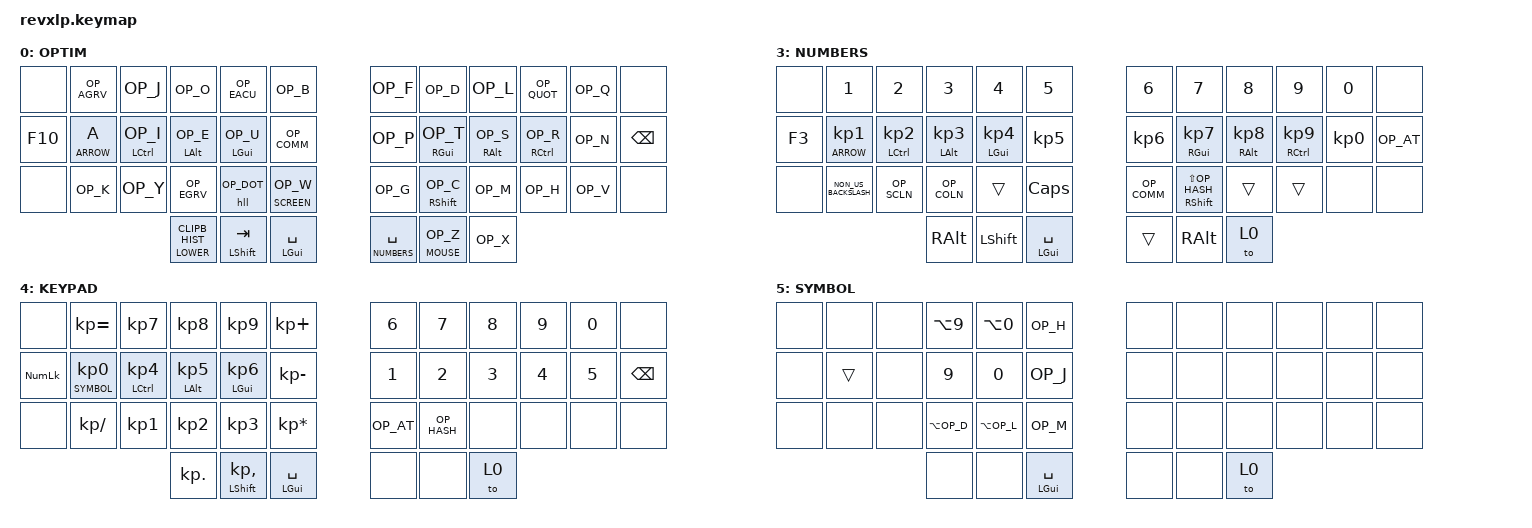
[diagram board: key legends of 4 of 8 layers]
/*
 * Copyright (c) 2020 The ZMK Contributors
 *
 * SPDX-License-Identifier: MIT
 */

#include <behaviors.dtsi>
#include <dt-bindings/zmk/keys.h>
#include <dt-bindings/zmk/bt.h>
// #include <dt-bindings/zmk/backlight.h>
#include <dt-bindings/zmk/pointing.h>
// #include "mouse.dtsi"
#include "keymap_optimot.h"

//APPLICATIONS SHORCUTS
    //Omniplan
    #define OMNIPLIDENTR LG(LS(N0))
    #define OMNIPLIDENTL LG(LS(N9))
    //1Password
    #define ONEPWDQUICK LS(LA(LG(OP_P)))
    //Raycast
    #define CLIPB_HIST LG(LA(OP_P))
    #define RAYCPNAME  LG(OP_DOT)
    #define RAYCPPHONE LG(LS(OP_DOT))
    #define RAYCPMAIL  LG(LS(OP_COMM))
    #define NEWRAYNOTE LA(LG(LS(OP_N)))
    #define RAYEMOJI   LC(LG(SPACE))
    //Outlook
    #define OUTLKARCHMAIL LC(OP_E)
    #define OUTLKFILEMAIL LG(LS(OP_M))

    #define OUTLKNEWMAINWINDOW LA(LG(LS(OP_N)))
    //TextExpander
    #define TEXTEXOFF RC(RA(LS(RG(OP_T))))
    #define TEXTEXSEARCH RG(LS(LA(OP_F)))
    //Hook
    #define HOOKCPYLK   LG(LC(LA(SPACE)))
    #define HOOKCPYMDLK LS(LA(LG(SPACE)))
    #define HOOKTOLINK  LC(LS(LG(SPACE)))
    #define HOOK        LG(LS(SPACE))
    //MACOS
    #define HIDEWINDOW LG(OP_M)


#define OPTIM   0
#define LOWER   1
#define MOUSE   2
#define NUMBERS 3
#define KEYPAD  4
#define SYMBOL  5
#define ARROW   6
#define SCREEN  7



/*                KEY POSITIONS

  ╭────────────────────────╮ ╭────────────────────────╮
  │  0   1   2   3   4   5 │ │  6   7   8   9  10  11 │
  │ 12  13  14  15  16  17 │ │ 18  19  20  21  22  23 │
  │ 24  25  26  27  28  29 │ │ 30  31  32  33  34  35 │
  ╰──────────╮  36  37  38 │ │ 39  40  41 ╭───────────╯
             ╰─────────────╯ ╰────────────╯            */

/*                KEY POSITIONS TOTEM

       ╭───────────────────╮ ╭────────────────────╮
       │ 0   1   2   3   4 │ │  5   6   7   8   9 │
  ╭────╯10  11  12  13  14 │ │ 15  16  17  18  19 ╰───╮
  │ 20  21  22  23  24  25 │ │ 26  27  28  29  30  31 │
  ╰──────────╮  32  33  34 │ │ 35  36  37 ╭───────────╯
             ╰─────────────╯ ╰────────────╯            */


&kscan0 { debounce-press-ms = <17>;
          debounce-release-ms = <17>;
        };

/ {
    macros {
        q_minuscule: q_minuscule {
            //label = "ZM_q_minuscul";
            compatible = "zmk,behavior-macro";
            //wait-ms = <40>;
            tap-ms = <40>;
            #binding-cells = <0>;
            bindings
                = <&macro_tap &kp CAPS>
                , <&macro_press &kp LSHFT>
                , <&macro_tap &kp OP_Q>
                , <&macro_release &kp LSHFT>
                , <&macro_tap &kp CAPS>
                ;
        };
        q_maj: q_maj {
            //label = "ZM_q_maj";
            compatible = "zmk,behavior-macro";
            //wait-ms = <40>;
            tap-ms = <40>;
            #binding-cells = <0>;
            bindings
                = <&macro_tap &kp CAPS>
                , <&macro_tap &kp OP_Q>
                , <&macro_tap &kp CAPS>
                ;
        };
        win_list: win_list {
            //label = "Current App Window list in Contexts App";
            compatible = "zmk,behavior-macro";
            tap-ms = <40>;
            #binding-cells = <0>;
            bindings
                = <&macro_press &mo ARROW &kp LGUI>
                , <&macro_tap &kp OP_QUOT>
                , <&macro_pause_for_release>
                , <&macro_release &mo ARROW &kp LGUI>
                ;
        };
        apps_list: apps_list {
            //label = "All Apps Window list in Contexts App";
            compatible = "zmk,behavior-macro";
            tap-ms = <40>;
            #binding-cells = <0>;
            bindings
                = <&macro_press &mo ARROW &kp LGUI>
                , <&macro_tap &kp TAB>
                , <&macro_pause_for_release>
                , <&macro_release &mo ARROW &kp LGUI>
                ;
        };
    };
};

#include "combos.dtsi" // This include **has** to be made **after** the layers' define, else it won't compile.

//Existing Behavior modifications :
//     &mt {
//     hold-while-undecided; //faster mod, used for CMD on left thumb key.
//     };

// Key position groups
#define KEYS_L 0 1 2 3 4 5 12 13 14 15 16 17 24 25 26 27 28 29
#define KEYS_R 6 7 8 9 10 11 18 19 20 21 22 23 30 31 32 33 34 35
#define KEYS_L_SPECIAL 1
#define THUMBS_L 36 37 38
#define THUMB_L_SPECIAL 37
#define THUMBS_R 39 40 41

/*                KEY POSITIONS

  ╭────────────────────────╮ ╭────────────────────────╮
  │  0   1   2   3   4   5 │ │  6   7   8   9  10  11 │
  │ 12  13  14  15  16  17 │ │ 18  19  20  21  22  23 │
  │ 24  25  26  27  28  29 │ │ 30  31  32  33  34  35 │
  ╰───────────╮ 36  37  38 │ │ 39  40  41 ╭───────────╯
              ╰────────────╯ ╰────────────╯            */

/ {
    behaviors {
        hml: homerow_mods_l {
            compatible = "zmk,behavior-hold-tap";
            //label = "ALPHA_MT_L";
            #binding-cells = <2>;
            tapping-term-ms = <250>;
            quick-tap-ms = <150>;
            flavor = "tap-preferred";
            bindings = <&kp>, <&kp>;
            //global-quick-tap-ms = <150>;
            require-prior-idle-ms = <100>;
            hold-trigger-key-positions = <KEYS_R KEYS_L_SPECIAL THUMBS_R THUMB_L_SPECIAL>;
            hold-trigger-on-release;
        };
        hmr: homerow_mods_r {
            compatible = "zmk,behavior-hold-tap";
            //label = "ALPHA_MT_R";
            #binding-cells = <2>;
            tapping-term-ms = <250>;
            quick-tap-ms = <150>;
            flavor = "tap-preferred";
            bindings = <&kp>, <&kp>;
            //global-quick-tap-ms = <150>;
            require-prior-idle-ms = <125>;
            hold-trigger-key-positions = <KEYS_L THUMBS_L>;
            hold-trigger-on-release;
        };
        hsl: homerow_shift_l {
            compatible = "zmk,behavior-hold-tap";
            //label = "ALPHA_SFT_L";
            #binding-cells = <2>;
            tapping-term-ms = <200>;
            quick-tap-ms = <150>;
            flavor = "hold-preferred";
            bindings = <&kp>, <&kp>;
            hold-trigger-key-positions = <KEYS_R KEYS_L THUMBS_R>;
            //hold-trigger-on-release;
        };
        hsr: homerow_shift_r {
            compatible = "zmk,behavior-hold-tap";
            //label = "ALPHA_SFT_R";
            #binding-cells = <2>;
            tapping-term-ms = <200>;
            quick-tap-ms = <100>;
            flavor = "tap-preferred";
            bindings = <&kp>, <&kp>;
            hold-trigger-key-positions = <KEYS_L THUMBS_L>;
        };   
        hlr: homerow_layer_r {
            compatible = "zmk,behavior-hold-tap";
            //label = "HOMEROW_LAYER_R";
            #binding-cells = <2>;
            tapping-term-ms = <200>;
            quick-tap-ms = <150>;
            flavor = "tap-preferred";
            bindings = <&mo>, <&kp>;
            require-prior-idle-ms = <125>;
            hold-trigger-key-positions = <KEYS_L THUMBS_L>;
            hold-trigger-on-release;
        };
        hll: homerow_layer_l {
            compatible = "zmk,behavior-hold-tap";
            //label = "HOMEROW_LAYER_L";
            #binding-cells = <2>;
            tapping-term-ms = <200>; // switched from 300 to 200, getting too much "af" instead of "@" (layer not triggered)
            quick-tap-ms = <150>; //trying to see what gives with 0 instead of 150 => not kept.
            flavor = "tap-preferred";
            bindings = <&mo>, <&kp>;
            require-prior-idle-ms = <125>;
            hold-trigger-key-positions = <KEYS_R THUMBS_L THUMBS_R>;
            hold-trigger-on-release;
        };
 /*       agrvtab: agrave_tab {
            compatible = "zmk,behavior-mod-morph";
            #binding-cells = <0>;
            bindings = <&kp OP_AGRV>, <&kp TAB>;
            mods = <(MOD_LGUI|MOD_RGUI)>;
            keep-mods = <(MOD_LGUI|MOD_RGUI)>;
        }; */
    }; 

/*                KEY POSITIONS

  ╭────────────────────────╮ ╭────────────────────────╮
  │  0   1   2   3   4   5 │ │  6   7   8   9  10  11 │
  │ 12  13  14  15  16  17 │ │ 18  19  20  21  22  23 │
  │ 24  25  26  27  28  29 │ │ 30  31  32  33  34  35 │
  ╰───────────╮ 36  37  38 │ │ 39  40  41 ╭───────────╯
              ╰────────────╯ ╰────────────╯            */

    keymap {
        compatible = "zmk,keymap";

        default_layer {
        display-name = "OPTIM";
// ---------------------------------------------------------------------------------------------------------------------
// |  TAB   |  À  |  J  |    O     |   É   |     B     |                   |  ^      |  V     |  D    |  L   |   J   | BKSPC |
// | LSHFT  |  A  |  I  |    E     |   U   |     ,     |                   |  C      |  T     |  S    |  R   |   N   |   M   |
// |MISSCTRL|  K  |  Y  |    È     |   .   |     W     |                   |  '      |  Q     |  G    |  H   |   F   |   Ç   |
//                     | LOWER /   |   X / | CMD/ENTER |                   | NUMBER/ | MOUSE/ | RC+SPC|
//                     | CLIPB HIST| LSHFT |                             | SPACE   |  W     | 
            bindings = <
&none   &kp OP_AGRV     &kp OP_J        &kp OP_O             &kp OP_EACU    &kp OP_B                     &kp OP_F           &kp OP_D        &kp OP_L       &kp OP_QUOT     &kp OP_Q &none
&kp F10 &hll ARROW A &hml LCTRL OP_I &hml LALT OP_E       &hml LGUI OP_U &kp OP_COMM                  &kp OP_P           &hmr RGUI OP_T  &hmr RALT OP_S &hmr RCTRL OP_R &kp OP_N &kp BSPC
&none   &kp OP_K     &kp OP_Y        &kp OP_EGRV          &hll OP_DOT    &hll SCREEN OP_W             &kp OP_G           &hsr RSHFT OP_C &kp OP_M       &kp OP_H        &kp OP_V &none
                                     &lt LOWER CLIPB_HIST &hsl LSHFT TAB &mt LGUI SPACE               &hlr NUMBERS SPACE &hlr MOUSE OP_Z &kp OP_X 
            >;
        };

        lower_layer {
        display-name = "LOWER";
// ----------------------------------------------------------------------------------------------------------------
// | ESC   |  F1 |  F2 |  F3  |  F4      |  F5  |                   |NextDisplay|Maximize Window|   8   |   9  |    0  |  F12  |
// |   F6  |  F7 |  F8 |  F9  |  F10     |  F11 |                   |  ^   |  &    |  *    |  (   |   )   |   |   |
// |       |  =  |  -  |  +   |DoNotDist |  F12 |                   |  [   |  ]    |  ;    |  :   |   \   |       |
//               |     |      |          |      |                   |      |       |       |      |
            bindings = <                       
&none  &kp F1        &kp F2         &kp F3        &kp F4  &kp F5            &kp LA(LC(LS(OP_F)))     &kp LA(LC(LS(OP_D)))     &kp LA(LC(LS(OP_L)))      &kp LA(LC(LS(OP_QUOT))) &none                 &none
&kp F3 &kp F6        &kp F7         &kp F8        &kp F9  &kp F10           &kp LA(LC(LS(LG(OP_P)))) &kp LA(LC(LS(LEFT)))     &kp LA(LC(LS(UP)))        &kp LA(LC(LS(DOWN)))    &kp LA(LC(LS(RIGHT))) &kp LG(F12)
&none  &kp RAYCPNAME &kp RAYCPPHONE &kp RAYCPMAIL &kp F11 &kp F12           &kp LA(LC(LS(OP_G)))     &kp LC(LG(OP_Q))         &kp LA(LC(LS(LG(OP_C))))  &kp LA(LC(LS(OP_H)))    &none                 &none
                                    &trans        &trans  &trans            &kp LG(LA(LC(LS(LEFT)))) &kp LG(LA(LC(LS(DOWN)))) &kp LG(LA(LC(LS(RIGHT))))      
            >;
        };

        mouse_layer {
        display-name = "MOUSE";
// -----------------------------------------------------------------------------------------------------------------------------------------------------------
// |                     |NewOmniFocTaskFromTxt| HOME       | MouseUP      |  END       |Spotlight|             |      |      |       |      |       |       |
// |NewOmniFocTaskFromTxt| INS                 | Mouseleft  | MouseDwn     | MouseRght  |      |                | PGUP |      |   ^   |      |       | OutlkNewMainWindow|
// |AppsForceQuit        | FileMailOutlook     | ZoomReset  | Zoom-        | Zoom+      |EMOJI |                |      |      |       |      |       |       |
//                                                          |              |            | Hook |                |      |      |       |
            bindings = <    
&none &kp LA(LC(LG(LS(OP_EACU)))) &kp LG(LEFT)   &mmv MOVE_UP   &kp LG(RIGHT)   &kp LA(LC(LS(SPACE)))          &kp C_MUTE &kp C_VOL_DN    &kp C_VOL_UP   &kp OUTLKFILEMAIL &kp HOME       &none
&none &none                       &mmv MOVE_LEFT &mmv MOVE_DOWN &mmv MOVE_RIGHT &none                          &kp PG_UP  &mkp LCLK       &mkp RCLK      &kp OUTLKARCHMAIL &kp END        &trans
&none &none                       &kp LG(N0)     &kp LG(OP_AT)  &kp LG(OP_HASH) &kp RAYEMOJI                   &kp PG_DN  &msc SCRL_RIGHT &msc SCRL_DOWN &msc SCRL_UP      &msc SCRL_LEFT &none
                                                     &trans     &trans          &trans                         &trans     &trans          &trans  
            >;
        };

        numbers_layer {
        display-name = "NUMBERS";
// ------------------------------------------------------------------------------------------------------------
// | TAB   |  «° |  °» |  "   |  -   |  +      |                   |  *   |  /    |  =    |  (   |   )   |  BSPC |
// | LSHFT |   1 |   2 |   3  |   4  |   5     |                   |   6  |   7   |   8   |   9  |    0  |   @/_ |
// | F10   | ??ê?? |  ;  |  :   |  .   |   &     |                   |  ,   |   No  |   No  |   H   |   No  |   #/% |
//                     | LCTRL| LALT |CMD/space|                   | togg | RCTRL | RALT  |
            bindings = <            
&none  &kp N1               &kp N2           &kp N3          &kp N4          &kp N5                   &kp N6      &kp N7                 &kp N8          &kp N9           &kp N0    &none
&kp F3 &hll ARROW KP_N1     &hml LCTRL KP_N2 &hml LALT KP_N3 &hml LGUI KP_N4 &kp KP_N5                &kp KP_N6   &hmr RGUI KP_N7        &hmr RALT KP_N8 &hmr RCTRL KP_N9 &kp KP_N0 &kp OP_AT
&none  &kp NON_US_BACKSLASH &kp OP_SCLN      &kp OP_COLN     &trans          &kp CAPS                 &kp OP_COMM &hsr RSHFT LS(OP_HASH) &trans          &trans           &none     &none
                                             &kp RALT        &kp LSHFT       &mt LGUI SPACE           &trans      &kp RALT               &to 0
            >;
        };

                keypad_layer {
// ┏━━━━━━━━━━━━━━━━━━━━━━━━━━━━━━━━━━━━━━━┓
display-name = "KEYPAD"                   ;
// ┗━━━━━━━━━━━━━━━━━━━━━━━━━━━━━━━━━━━━━━━┛
//             ┏━━━━━━━━━━━┳━━━━━━━━━━━┳━━━━━━━━━━━┳━━━━━━━━━━━┳━━━━━━━━━━━┓   ┏━━━━━━━━━━━┳━━━━━━━━━━━┳━━━━━━━━━━━┳━━━━━━━━━━━┳━━━━━━━━━━━┓
//             ┃           ┃           ┃           ┃           ┃           ┃   ┃           ┃    F7     ┃    F8     ┃    F9     ┃    F12    ┃
//             ┣━━━━━━━━━━━╋━━━━━━━━━━━╋━━━━━━━━━━━╋━━━━━━━━━━━╋━━━━━━━━━━━┫   ┣━━━━━━━━━━━╋━━━━━━━━━━━╋━━━━━━━━━━━╋━━━━━━━━━━━╋━━━━━━━━━━━┫
//             ┃           ┃           ┃           ┃           ┃           ┃   ┃           ┃    F4     ┃    F5     ┃    F6     ┃    F11    ┃
// ┏━━━━━━━━━━━╋━━━━━━━━━━━╋━━━━━━━━━━━╋━━━━━━━━━━━╋━━━━━━━━━━━╋━━━━━━━━━━━┫   ┣━━━━━━━━━━━╋━━━━━━━━━━━╋━━━━━━━━━━━╋━━━━━━━━━━━╋━━━━━━━━━━━╋━━━━━━━━━━━┓
// ┃           ┃           ┃           ┃           ┃           ┃           ┃   ┃           ┃    F1     ┃    F2     ┃    F3     ┃    F10    ┃           ┃
// ┗━━━━━━━━━━━┻━━━━━━━━━━━┻━━━━━━━━━━━╋━━━━━━━━━━━╋━━━━━━━━━━━╋━━━━━━━━━━━┫   ┣━━━━━━━━━━━╋━━━━━━━━━━━╋━━━━━━━━━━━╋━━━━━━━━━━━┻━━━━━━━━━━━┻━━━━━━━━━━━┛
//                                     ┃           ┃           ┃           ┃   ┃           ┃           ┃           ┃
//                                     ┗━━━━━━━━━━━┻━━━━━━━━━━━┻━━━━━━━━━━━┛   ┗━━━━━━━━━━━┻━━━━━━━━━━━┻━━━━━━━━━━━┛
 bindings = <
// ╷           ╷           ╷           ╷           ╷           ╷           ╷   ╷           ╷           ╷           ╷           ╷           ╷           ╷

&none          &kp KP_EQUAL      &kp KP_N7        &kp KP_N8        &kp KP_N9           &kp KP_PLUS                 &kp N6      &kp N7      &kp N8 &kp N9 &kp N0 &none   
&kp KP_NUMLOCK &hll SYMBOL KP_N0 &hml LCTRL KP_N4 &hml LALT KP_N5  &hml LGUI KP_N6     &kp KP_MINUS                &kp N1      &kp N2      &kp N3 &kp N4 &kp N5 &kp BSPC
&none          &kp KP_SLASH      &kp KP_N1        &kp KP_N2        &kp KP_N3           &kp KP_MULTIPLY             &kp OP_AT   &kp OP_HASH &none  &none  &none  &none
                                                  &kp KP_DOT       &hsl LSHFT KP_COMMA &mt LGUI SPACE              &none       &none       &to 0
                        >;
                };

                symbol_layer {
// ┏━━━━━━━━━━━━━━━━━━━━━━━━━━━━━━━━━━━━━━━┓
display-name = "SYMBOL"                   ;
// ┗━━━━━━━━━━━━━━━━━━━━━━━━━━━━━━━━━━━━━━━┛
//             ┏━━━━━━━━━━━┳━━━━━━━━━━━┳━━━━━━━━━━━┳━━━━━━━━━━━┳━━━━━━━━━━━┓   ┏━━━━━━━━━━━┳━━━━━━━━━━━┳━━━━━━━━━━━┳━━━━━━━━━━━┳━━━━━━━━━━━┓
//             ┃           ┃           ┃           ┃           ┃           ┃   ┃           ┃    F7     ┃    F8     ┃    F9     ┃    F12    ┃
//             ┣━━━━━━━━━━━╋━━━━━━━━━━━╋━━━━━━━━━━━╋━━━━━━━━━━━╋━━━━━━━━━━━┫   ┣━━━━━━━━━━━╋━━━━━━━━━━━╋━━━━━━━━━━━╋━━━━━━━━━━━╋━━━━━━━━━━━┫
//             ┃           ┃           ┃           ┃           ┃           ┃   ┃           ┃    F4     ┃    F5     ┃    F6     ┃    F11    ┃
// ┏━━━━━━━━━━━╋━━━━━━━━━━━╋━━━━━━━━━━━╋━━━━━━━━━━━╋━━━━━━━━━━━╋━━━━━━━━━━━┫   ┣━━━━━━━━━━━╋━━━━━━━━━━━╋━━━━━━━━━━━╋━━━━━━━━━━━╋━━━━━━━━━━━╋━━━━━━━━━━━┓
// ┃           ┃           ┃           ┃           ┃           ┃           ┃   ┃           ┃    F1     ┃    F2     ┃    F3     ┃    F10    ┃           ┃
// ┗━━━━━━━━━━━┻━━━━━━━━━━━┻━━━━━━━━━━━╋━━━━━━━━━━━╋━━━━━━━━━━━╋━━━━━━━━━━━┫   ┣━━━━━━━━━━━╋━━━━━━━━━━━╋━━━━━━━━━━━╋━━━━━━━━━━━┻━━━━━━━━━━━┻━━━━━━━━━━━┛
//                                     ┃           ┃           ┃           ┃   ┃           ┃           ┃           ┃
//                                     ┗━━━━━━━━━━━┻━━━━━━━━━━━┻━━━━━━━━━━━┛   ┗━━━━━━━━━━━┻━━━━━━━━━━━┻━━━━━━━━━━━┛
 bindings = <
// ╷           ╷           ╷           ╷           ╷           ╷           ╷   ╷           ╷           ╷           ╷           ╷           ╷           ╷

&none &none   &none &kp LA(N9)   &kp LA(N0)   &kp OP_H                &none &none &none &none &none &none
&none &trans  &none &kp N9       &kp N0       &kp OP_J                &none &none &none &none &none &none
&none &none   &none &kp LA(OP_D) &kp LA(OP_L) &kp OP_M                &none &none &none &none &none &none
                    &none        &none        &mt LGUI SPACE          &none &none &to 0
                        >;
                };

        arrow_layer {
        display-name = "ARROW";
// ----------------------------------------------------------------------------------------------------------------------------------------------------------------
// | TO 0  | none| OMNIPLIDENTR     | OMNIPLIDENTL         | WkfyMirror  |  BSPC     |                   |  @   |  Rycst-MenuCmd  |  none  |  none   |  q    |      |
// | Trans |Trans|          |              |             |  1PassWD  |                   |  #   |  Left           |  UP    |  Down   | Right   |  None |
// | RESET |     |HookCpyLk | HookCpyMDLk  | HookToLink  |   Hook    |                   |  ??ê?? |  $/€          |PGUP|PGDWN|TxTXSearch|TxTXDisable|
//                          |              |   LSHFT     |CMD/return |                   |  SPC |WkfyPrev         |WkfyNext|
            bindings = <
&none       &to 0  &kp OMNIPLIDENTL &kp OMNIPLIDENTR &kp LG(LS(OP_M)) &kp BSPC                    &kp LS(LA(LG(N8))) &none       &kp LA(BSPC)  &kp LG(BSPC) &kp BSPC         &none
&bootloader &trans &kp LCTRL        &kp LALT         &kp LGUI         &kp ONEPWDQUICK             &kp OP_CIR         &kp LEFT    &kp UP        &kp DOWN     &kp RIGHT        &kp TEXTEXOFF
&none       &none  &kp HOOKCPYLK    &kp HOOKCPYMDLK  &kp HOOKTOLINK   &kp LS(F3)                  &kp LS(OP_DLR)     &kp OP_CCED &kp OP_DLR    &trans       &kp TEXTEXSEARCH &none
                                    &kp ESC          &trans           &trans                      &trans             &trans      &trans
            >;
        };

         screen_layer {
         display-name = "SCREEN";
// TODO: update layer description
// ------------------------------------------------------------------------------------------------------------
// |     |     |     |     |     |     |                   |            |     |     |     |     |     |
// |     |     |     |     |     |     |                   |            |     |     |     |     |     |
// |     |     |     |     |     |     |                   |MuteMicTeams|     |     |     |     |     |
//                   |     |     |     |                   |            |     |     |

            bindings = <
&none      &bt BT_SEL 0 &bt BT_SEL 1 &bt BT_SEL 2 &bt BT_SEL 3 &bt BT_SEL 4                 &kp LC(LS(OP_QUOT)) &kp C_PREV         &kp C_PP       &kp C_NEXT         &trans         &none
&none      &none        &none        &none        &none        &none                        &kp LC(LS(S))       &kp LG(LC(LS(N4))) &kp LG(LS(N4)) &kp LG(LC(LS(N3))) &kp LG(LS(N3)) &none
//&bl BL_TOG &none        &none        &none        &none        &none                        &kp LC(LS(S))       &kp LG(LC(LS(N4))) &kp LG(LS(N4)) &kp LG(LC(LS(N3))) &kp LG(LS(N3)) &bl BL_CYCLE
&none      &none        &none        &none        &none        &trans                       &kp LG(LS(OP_M))    &kp LG(LS(N9))     &kp RG(RS(UP)) &kp RG(RS(DOWN))   &kp LG(LS(N0)) &none
                                     &bt BT_CLR   &none        &none                        &kp SPACE           &kp LG(OP_COMM)    &kp LG(OP_DOT)
            >;
        };
   };
};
